# AT90PWM3 device description
Architecture: AVR8; Family: megaAVR
Registers are 8-bit, access not given, no defined reset value unless marked. A register's access mark holds for its fields unless they carry their own. Offsets are from the block's base; [hi:lo] are bit positions; {n}, {i} and the like mark numbered series; 'fields as' and 'values as' point back to an identical list.

## EEPROM
Instances: EEPROM 0x00
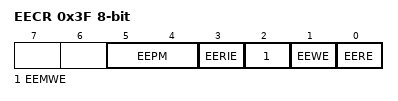
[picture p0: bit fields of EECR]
0x3F EECR — EEPROM Control Register
  [5:4] EEPM — EEPROM Programming Mode
  [3] EERIE — EEPROM Ready Interrupt Enable
  [2] EEMWE — EEPROM Master Write Enable
  [1] EEWE — EEPROM Write Enable
  [0] EERE — EEPROM Read Enable
0x40 EEDR — EEPROM Data Register
  [7:0] EEDR — EEPROM Data Bits
0x41 EEAR 16-bit — EEPROM Read/Write Access Bytes
  [11:0] EEAR — EEPROM Address bytes

## PSC0 — Power Stage Controller
Instances: PSC0 0x00
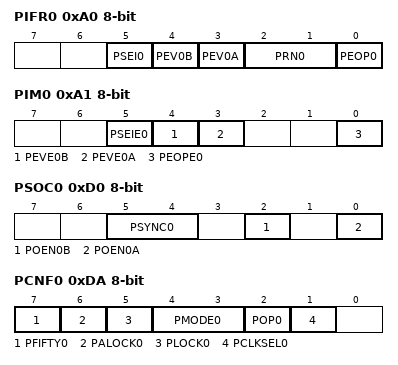
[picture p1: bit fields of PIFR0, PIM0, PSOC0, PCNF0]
0xA0 PIFR0 — PSC0 Interrupt Flag Register
  [5] PSEI0 — PSC 0 Synchro Error Interrupt
  [4] PEV0B — External Event B Interrupt
  [3] PEV0A — External Event A Interrupt
  [2:1] PRN0 — Ramp Number
    {v}={v+1} (v=0..3)
  [0] PEOP0 — End of PSC0 Interrupt
0xA1 PIM0 — PSC0 Interrupt Mask Register
  [5] PSEIE0 — PSC 0 Synchro Error Interrupt Enable
  [4] PEVE0B — External Event B Interrupt Enable
  [3] PEVE0A — External Event A Interrupt Enable
  [0] PEOPE0 — End of Cycle Interrupt Enable
0xD0 PSOC0 — PSC0 Synchro and Output Configuration
  [5:4] PSYNC0 — Synchronization Out for ADC Selection
    0=SEND_SIGNAL_ON_LEADING_EDGE_OF_PSCOUTN0; 1=SEND_SIGNAL_ON_TRAILING_EDGE_OF_PSCOUTN0; 2=SEND_SIGNAL_ON_LEADING_EDGE_OF_PSCOUTN1; 3=SEND_SIGNAL_ON_TRAILING_EDGE_OF_PSCOUTN1
  [2] POEN0B — PSCOUT01 Output Enable
  [0] POEN0A — PSCOUT00 Output Enable
0xD2 OCR0SA 16-bit — Output Compare 0 SA Register
  [11:0] OCR0SA — Output Compare SA
0xD4 OCR0RA 16-bit — Output Compare 0 RA Register
  [11:0] OCR0RA — Output Compare RA
0xD6 OCR0SB 16-bit — Output Compare 0 SB Register
  [11:0] OCR0SB — Output Compare SB
0xD8 OCR0RB 16-bit — Output Compare 0 RB Register
  [15:0] OCR0RB — Output Compare RB
0xDA PCNF0 — PSC 0 Configuration Register
  [7] PFIFTY0 — PSC 0 Fifty
  [6] PALOCK0 — PSC 0 Autolock
  [5] PLOCK0 — PSC 0 Lock
  [4:3] PMODE0 — PSC 0 Mode
    0=ONE_RAMP_MODE; 1=TWO_RAMP_MODE; 2=FOUR_RAMP_MODE; 3=CENTER_ALIGNED_MODE
  [2] POP0 — PSC 0 Output Polarity
  [1] PCLKSEL0 — PSC 0 Input Clock Select
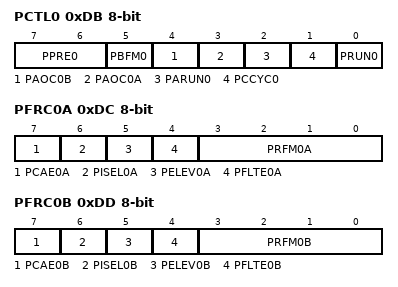
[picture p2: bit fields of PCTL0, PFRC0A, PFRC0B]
0xDB PCTL0 — PSC 0 Control Register
  [7:6] PPRE0 — PSC 0 Prescaler Selects
    0=NO_DIVIDER_ON_PSC_INPUT_CLOCK; 1=DIVIDE_THE_PSC_INPUT_CLOCK_BY_4; 2=DIVIDE_THE_PSC_INPUT_CLOCK_BY_16; 3=DIVIDE_THE_PSC_INPUT_CLOCK_BY_64
  [5] PBFM0 — PSC 0 Balance Flank Width Modulation
  [4] PAOC0B — PSC 0 Asynchronous Output Control B
  [3] PAOC0A — PSC 0 Asynchronous Output Control A
  [2] PARUN0 — PSC0 Auto Run
  [1] PCCYC0 — PSC0 Complete Cycle
  [0] PRUN0 — PSC 0 Run
0xDC PFRC0A — PSC 0 Input A Control
  [7] PCAE0A — PSC 0 Capture Enable Input Part A
  [6] PISEL0A — PSC 0 Input Select for Part A
  [5] PELEV0A — PSC 0 Edge Level Selector on Input Part A
  [4] PFLTE0A — PSC 0 Filter Enable on Input Part A
  [3:0] PRFM0A — PSC 0 Retrigger and Fault Mode for Part A
    0=NO_ACTION_PSC_INPUT_IS_IGNORED; 1=STOP_SIGNAL_JUMP_TO_OPPOSITE_DEAD_TIME_AND_WAIT; 2=STOP_SIGNAL_EXECUTE_OPPOSITE_DEAD_TIME_AND_WAIT; 3=STOP_SIGNAL_EXECUTE_OPPOSITE_WHILE_FAULT_ACTIVE; 4=DEACTIVATE_OUTPUTS_WITHOUT_CHANGING_TIMING; 5=STOP_SIGNAL_AND_INSERT_DEAD_TIME; 6=STOP_SIGNAL_JUMP_TO_OPPOSITE_DEAD_TIME_AND_WAIT; 7=HALT_PSC_AND_WAIT_FOR_SOFTWARE_ACTION; 8=EDGE_RETRIGGER_PSC; 9=FIXED_FREQUENCY_EDGE_RETRIGGER_PSC; {v}=RESERVED_DO_NOT_USE (v=10..13); 14=FIXED_FREQUENCY_EDGE_RETRIGGER_PSC_AND_DISACTIVATE_OUTPUT (Fixed Frequency Edge Retrigger PSC and Deactivate Output); 15=RESERVED_DO_NOT_USE
0xDD PFRC0B — PSC 0 Input B Control
  [7] PCAE0B — PSC 0 Capture Enable Input Part B
  [6] PISEL0B — PSC 0 Input Select for Part B
  [5] PELEV0B — PSC 0 Edge Level Selector on Input Part B
  [4] PFLTE0B — PSC 0 Filter Enable on Input Part B
  [3:0] PRFM0B — PSC 0 Retrigger and Fault Mode for Part B
    values as PFRC0A.PRFM0A
0xDE PICR0 16-bit — PSC 0 Input Capture Register
  [11:0] PICR0 — PSC 0 Input Capture Bytes
